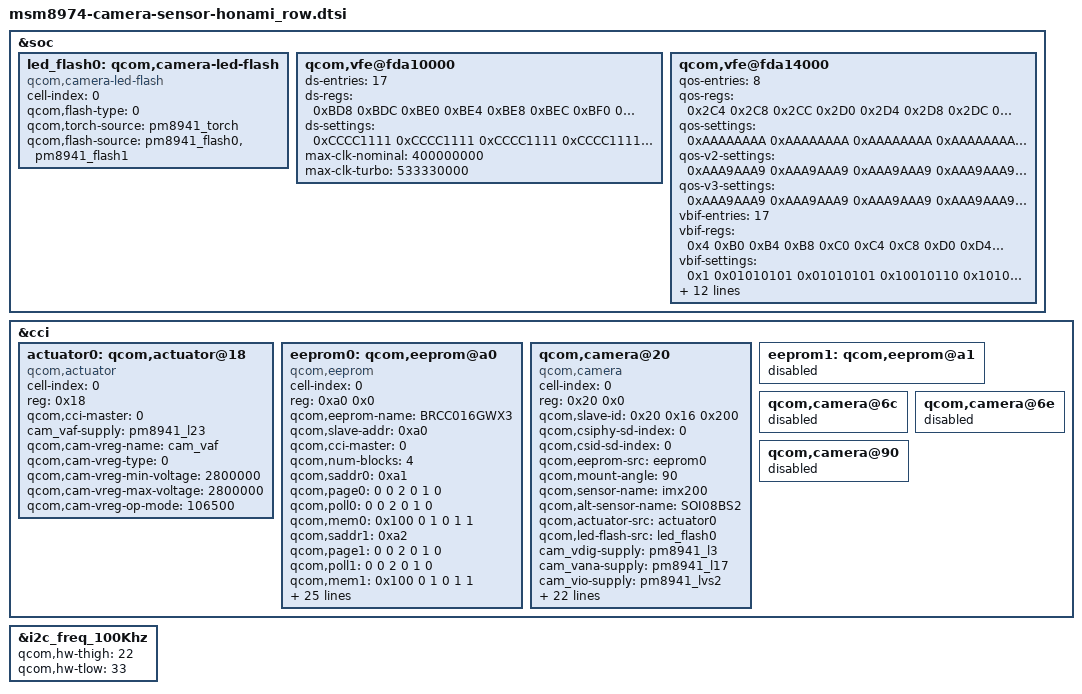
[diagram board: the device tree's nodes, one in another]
/*
 * Copyright (C) 2015 Sony Mobile Communications Inc.
 *
 * This program is free software; you can redistribute it and/or modify
 * it under the terms of the GNU General Public License version 2 and
 * only version 2 as published by the Free Software Foundation.
 *
 * This program is distributed in the hope that it will be useful,
 * but WITHOUT ANY WARRANTY; without even the implied warranty of
 * MERCHANTABILITY or FITNESS FOR A PARTICULAR PURPOSE.  See the
 * GNU General Public License for more details.
 */

&soc {
	led_flash0: qcom,camera-led-flash {
		cell-index = <0>;
		compatible = "qcom,camera-led-flash";
		qcom,flash-type = <0>;
		qcom,torch-source = <&pm8941_torch>;
		qcom,flash-source = <&pm8941_flash0 &pm8941_flash1>;
	};
/* **************** VFE CONFIGURATION START ************** */
/* NOTE: Main node is &soc */
	qcom,vfe@fda10000 {
		ds-entries = <17>;
		ds-regs = <0xBD8 0xBDC 0xBE0 0xBE4 0xBE8
			   0xBEC 0xBF0 0xBF4 0xBF8 0xBFC 0xC00
			   0xC04 0xC08 0xC0C 0xC10 0xC14 0xC18>;
		ds-settings = <0xCCCC1111 0xCCCC1111 0xCCCC1111
				0xCCCC1111 0xCCCC1111 0xCCCC1111
				0xCCCC1111 0xCCCC1111 0xCCCC1111
				0xCCCC1111 0xCCCC1111 0xCCCC1111
				0xCCCC1111 0xCCCC1111 0xCCCC1111
				0xCCCC1111 0x00000103>;
		max-clk-nominal = <400000000>;
		max-clk-turbo = <533330000>;
	};

	qcom,vfe@fda14000 {
		qos-entries = <8>;
		qos-regs = <0x2C4 0x2C8 0x2CC 0x2D0 0x2D4 0x2D8
			    0x2DC 0x2E0>;
		qos-settings = <0xAAAAAAAA 0xAAAAAAAA 0xAAAAAAAA
				0xAAAAAAAA 0xAAAAAAAA 0xAAAAAAAA
				0xAAAAAAAA 0x0002AAAA>;
		qos-v2-settings = <0xAAA9AAA9 0xAAA9AAA9 0xAAA9AAA9
				   0xAAA9AAA9 0xAAA9AAA9 0xAAA9AAA9
				   0xAAA9AAA9 0x0001AAA9>;
		qos-v3-settings = <0xAAA9AAA9 0xAAA9AAA9 0xAAA9AAA9
				   0xAAA9AAA9 0xAAA9AAA9 0xAAA9AAA9
				   0xAAA9AAA9 0x0001AAA9>;
		vbif-entries = <17>;
		vbif-regs = <0x4 0xB0 0xB4 0xB8 0xC0 0xC4 0xC8 0xD0
			     0xD4 0xD8 0xDC 0xF0 0x178 0x17C 0x124 0x160
			     0x164>;
		vbif-settings = <0x1 0x01010101 0x01010101 0x10010110
				 0x10101010 0x10101010 0x10101010 0x00001010
				 0x00001010 0x00000707 0x00000707 0x00000030
				 0x00000FFF 0x0FFF0FFF 0x00000001 0x22222222
				 0x00002222>;
		vbif-v2-entries = <16>;
		vbif-v2-regs = <0x4 0xB0 0xB4 0xB8 0xC0 0xC4 0xC8 0xD0
				0xD4 0xD8 0xF0 0x178 0x17C 0x124 0x160
				0x164>;
		vbif-v2-settings = <0x1 0x10101010 0x10101010 0x10101010
				    0x10101010 0x10101010 0x10101010 0x00000010
				    0x00000010 0x00000707 0x00000010 0x00000FFF
				    0x0FFF0FFF 0x00000003 0x22222222 0x00002222>;
		ds-entries = <17>;
		ds-regs = <0xBD8 0xBDC 0xBE0 0xBE4 0xBE8
			   0xBEC 0xBF0 0xBF4 0xBF8 0xBFC 0xC00
			   0xC04 0xC08 0xC0C 0xC10 0xC14 0xC18>;
		ds-settings = <0xCCCC1111 0xCCCC1111 0xCCCC1111
				0xCCCC1111 0xCCCC1111 0xCCCC1111
				0xCCCC1111 0xCCCC1111 0xCCCC1111
				0xCCCC1111 0xCCCC1111 0xCCCC1111
				0xCCCC1111 0xCCCC1111 0xCCCC1111
				0xCCCC1111 0x00000103>;
		max-clk-nominal = <400000000>;
		max-clk-turbo = <533330000>;
	};
/* **************** VFE CONFIGURATION  END  ************** */
};

&cci {
	actuator0: qcom,actuator@18 {
		cell-index = <0>;
		reg = <0x18>;
		compatible = "qcom,actuator";
		qcom,cci-master = <0>;
		cam_vaf-supply = <&pm8941_l23>;
		qcom,cam-vreg-name = "cam_vaf";
		qcom,cam-vreg-type = <0>;
		qcom,cam-vreg-min-voltage = <2800000>;
		qcom,cam-vreg-max-voltage = <2800000>;
		qcom,cam-vreg-op-mode = <106500>;
	};

	eeprom0: qcom,eeprom@a0 {
		cell-index = <0>;
		reg = <0xa0 0x0>;
		qcom,eeprom-name = "BRCC016GWX3";
		compatible	= "qcom,eeprom";
		qcom,slave-addr	= <0xa0>;
		qcom,cci-master	= <0>;
		qcom,num-blocks = <4>;

		/* Note: 2048b long. Name in first block. */
		qcom,saddr0 = <0xa1>;
		qcom,page0 = <0 0 2 0 1 0>;
		qcom,poll0 = <0 0 2 0 1 0>;
		qcom,mem0 = <0x100 0 1 0 1 1>;

		qcom,saddr1 = <0xa2>;
		qcom,page1 = <0 0 2 0 1 0>;
		qcom,poll1 = <0 0 2 0 1 0>;
		qcom,mem1 = <0x100 0 1 0 1 1>;

		qcom,saddr2 = <0xa3>;
		qcom,page2 = <0 0 2 0 1 0>;
		qcom,poll2 = <0 0 2 0 1 0>;
		qcom,mem2 = <0x100 0 1 0 1 1>;

		qcom,saddr3 = <0xa4>;
		qcom,page3 = <0 0 2 0 1 0>;
		qcom,poll3 = <0 0 2 0 1 0>;
		qcom,mem3 = <0x100 0 1 0 1 1>;

		cam_vdig-supply = <&pm8941_l3>;
		cam_vana-supply = <&pm8941_l17>;
		cam_vio-supply = <&pm8941_lvs2>;
		cam_vaf-supply = <&pm8941_l23>; /* remove? */
		qcom,cam-vreg-name = "cam_vio";
		qcom,cam-vreg-type = <0>;
		qcom,cam-vreg-min-voltage = <0>;
		qcom,cam-vreg-max-voltage = <0>;
		qcom,cam-vreg-op-mode = <0>;
		qcom,gpio-no-mux = <0>;

		qcom,csi-lane-assign = <0x4320>;
		qcom,csi-lane-mask = <0x1F>;

		qcom,cam-power-seq-type = "sensor_vreg", "sensor_i2c_mux";
		qcom,cam-power-seq-val = "cam_vio", "none";
		qcom,cam-power-seq-cfg-val = <0 1>;
		qcom,cam-power-seq-delay = <1 1>;
	};

	qcom,camera@20 {
		cell-index = <0>;
		compatible = "qcom,camera";
		reg = <0x20 0x0>;
		status = "ok";
		qcom,slave-id = <0x20 0x16 0x200>;
		qcom,csiphy-sd-index = <0>;
		qcom,csid-sd-index = <0>;
		qcom,eeprom-src = <&eeprom0>;
		qcom,mount-angle = <90>;
		qcom,sensor-name = "imx200";
		qcom,alt-sensor-name = "SOI08BS2";
		qcom,actuator-src = <&actuator0>;
		qcom,led-flash-src = <&led_flash0>;
		cam_vdig-supply = <&pm8941_l3>;
		cam_vana-supply = <&pm8941_l17>;
		cam_vio-supply = <&pm8941_lvs2>;
		qcom,cam-vreg-name =
			"cam_vdig",
			"cam_vio",
			"cam_vana";
		qcom,cam-vreg-type = <0 0 0>;
		qcom,cam-vreg-min-voltage = <1200000 0 2700000>;
		qcom,cam-vreg-max-voltage = <1200000 0 2700000>;
		qcom,cam-vreg-op-mode = <85000 0 103000>;
		qcom,gpio-no-mux = <0>;
		gpios = <&msmgpio 15 0>, <&msmgpio 94 0>;
		qcom,gpio-reset = <1>;
		qcom,gpio-req-tbl-num = <0 1>;
		qcom,gpio-req-tbl-flags = <1 0>;
		qcom,gpio-req-tbl-label = "CAMIF_MCLK", "CAM_RESET1";
		qcom,gpio-set-tbl-num = <1 1>;
		qcom,gpio-set-tbl-flags = <0 2>;
		qcom,gpio-set-tbl-delay = <1000 1000>;
		qcom,csi-lane-assign = <0x4320>;
		qcom,csi-lane-mask = <0x1F>;
		qcom,sensor-position = <0>;
		qcom,sensor-mode = <0>;
		qcom,sensor-type = <0>;
		qcom,cci-master = <0>;
	};

	eeprom1: qcom,eeprom@a1 {
		status = "disabled";
	};

	qcom,camera@6c {
		status = "disabled";
	};

	/* disable Qualcomm camera sensors */
	qcom,camera@6e {
		status = "disabled";
	};

	qcom,camera@90 {
		status = "disabled";
	};

};

&i2c_freq_100Khz {
	qcom,hw-thigh = <22>;
	qcom,hw-tlow = <33>;
};
